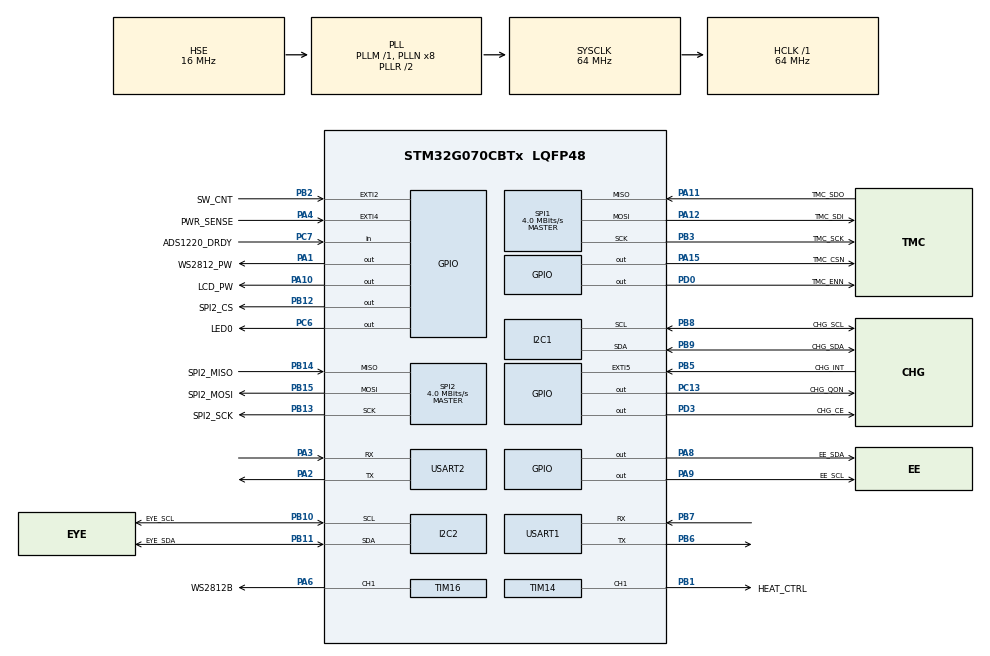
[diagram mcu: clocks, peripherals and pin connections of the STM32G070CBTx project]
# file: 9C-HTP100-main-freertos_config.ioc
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Dma.I2C1_RX.0.Direction=DMA_PERIPH_TO_MEMORY
Dma.I2C1_RX.0.EventEnable=DISABLE
Dma.I2C1_RX.0.Instance=DMA1_Channel1
Dma.I2C1_RX.0.MemDataAlignment=DMA_MDATAALIGN_BYTE
Dma.I2C1_RX.0.MemInc=DMA_MINC_ENABLE
Dma.I2C1_RX.0.Mode=DMA_NORMAL
Dma.I2C1_RX.0.PeriphDataAlignment=DMA_PDATAALIGN_BYTE
Dma.I2C1_RX.0.PeriphInc=DMA_PINC_DISABLE
Dma.I2C1_RX.0.Polarity=HAL_DMAMUX_REQ_GEN_RISING
Dma.I2C1_RX.0.Priority=DMA_PRIORITY_LOW
Dma.I2C1_RX.0.RequestNumber=1
Dma.I2C1_RX.0.SignalID=NONE
Dma.I2C1_RX.0.SyncEnable=DISABLE
Dma.I2C1_RX.0.SyncPolarity=HAL_DMAMUX_SYNC_NO_EVENT
Dma.I2C1_RX.0.SyncRequestNumber=1
Dma.I2C1_RX.0.SyncSignalID=NONE
Dma.I2C1_TX.1.Direction=DMA_MEMORY_TO_PERIPH
Dma.I2C1_TX.1.EventEnable=DISABLE
Dma.I2C1_TX.1.Instance=DMA1_Channel2
Dma.I2C1_TX.1.MemDataAlignment=DMA_MDATAALIGN_BYTE
Dma.I2C1_TX.1.MemInc=DMA_MINC_ENABLE
Dma.I2C1_TX.1.Mode=DMA_NORMAL
Dma.I2C1_TX.1.PeriphDataAlignment=DMA_PDATAALIGN_BYTE
Dma.I2C1_TX.1.PeriphInc=DMA_PINC_DISABLE
Dma.I2C1_TX.1.Polarity=HAL_DMAMUX_REQ_GEN_RISING
Dma.I2C1_TX.1.Priority=DMA_PRIORITY_LOW
Dma.I2C1_TX.1.RequestNumber=1
Dma.I2C1_TX.1.SignalID=NONE
Dma.I2C1_TX.1.SyncEnable=DISABLE
Dma.I2C1_TX.1.SyncPolarity=HAL_DMAMUX_SYNC_NO_EVENT
Dma.I2C1_TX.1.SyncRequestNumber=1
Dma.I2C1_TX.1.SyncSignalID=NONE
Dma.I2C2_RX.2.Direction=DMA_PERIPH_TO_MEMORY
Dma.I2C2_RX.2.EventEnable=DISABLE
Dma.I2C2_RX.2.Instance=DMA1_Channel3
Dma.I2C2_RX.2.MemDataAlignment=DMA_MDATAALIGN_BYTE
Dma.I2C2_RX.2.MemInc=DMA_MINC_ENABLE
Dma.I2C2_RX.2.Mode=DMA_NORMAL
Dma.I2C2_RX.2.PeriphDataAlignment=DMA_PDATAALIGN_BYTE
Dma.I2C2_RX.2.PeriphInc=DMA_PINC_DISABLE
Dma.I2C2_RX.2.Polarity=HAL_DMAMUX_REQ_GEN_RISING
Dma.I2C2_RX.2.Priority=DMA_PRIORITY_LOW
Dma.I2C2_RX.2.RequestNumber=1
Dma.I2C2_RX.2.SignalID=NONE
Dma.I2C2_RX.2.SyncEnable=DISABLE
Dma.I2C2_RX.2.SyncPolarity=HAL_DMAMUX_SYNC_NO_EVENT
Dma.I2C2_RX.2.SyncRequestNumber=1
Dma.I2C2_RX.2.SyncSignalID=NONE
Dma.I2C2_TX.3.Direction=DMA_MEMORY_TO_PERIPH
Dma.I2C2_TX.3.EventEnable=DISABLE
Dma.I2C2_TX.3.Instance=DMA1_Channel4
Dma.I2C2_TX.3.MemDataAlignment=DMA_MDATAALIGN_BYTE
Dma.I2C2_TX.3.MemInc=DMA_MINC_ENABLE
Dma.I2C2_TX.3.Mode=DMA_NORMAL
Dma.I2C2_TX.3.PeriphDataAlignment=DMA_PDATAALIGN_BYTE
Dma.I2C2_TX.3.PeriphInc=DMA_PINC_DISABLE
Dma.I2C2_TX.3.Polarity=HAL_DMAMUX_REQ_GEN_RISING
Dma.I2C2_TX.3.Priority=DMA_PRIORITY_LOW
Dma.I2C2_TX.3.RequestNumber=1
Dma.I2C2_TX.3.SignalID=NONE
Dma.I2C2_TX.3.SyncEnable=DISABLE
Dma.I2C2_TX.3.SyncPolarity=HAL_DMAMUX_SYNC_NO_EVENT
Dma.I2C2_TX.3.SyncRequestNumber=1
Dma.I2C2_TX.3.SyncSignalID=NONE
Dma.Request0=I2C1_RX
Dma.Request1=I2C1_TX
Dma.Request2=I2C2_RX
Dma.Request3=I2C2_TX
Dma.Request4=TIM16_CH1
Dma.Request5=USART2_RX
Dma.TIM16_CH1.4.Direction=DMA_MEMORY_TO_PERIPH
Dma.TIM16_CH1.4.EventEnable=DISABLE
Dma.TIM16_CH1.4.Instance=DMA1_Channel7
Dma.TIM16_CH1.4.MemDataAlignment=DMA_MDATAALIGN_HALFWORD
Dma.TIM16_CH1.4.MemInc=DMA_MINC_ENABLE
Dma.TIM16_CH1.4.Mode=DMA_CIRCULAR
Dma.TIM16_CH1.4.PeriphDataAlignment=DMA_PDATAALIGN_HALFWORD
Dma.TIM16_CH1.4.PeriphInc=DMA_PINC_DISABLE
Dma.TIM16_CH1.4.Polarity=HAL_DMAMUX_REQ_GEN_RISING
Dma.TIM16_CH1.4.Priority=DMA_PRIORITY_LOW
Dma.TIM16_CH1.4.RequestNumber=1
Dma.TIM16_CH1.4.SignalID=NONE
Dma.TIM16_CH1.4.SyncEnable=DISABLE
Dma.TIM16_CH1.4.SyncPolarity=HAL_DMAMUX_SYNC_NO_EVENT
Dma.TIM16_CH1.4.SyncRequestNumber=1
Dma.TIM16_CH1.4.SyncSignalID=NONE
Dma.USART2_RX.5.Direction=DMA_PERIPH_TO_MEMORY
Dma.USART2_RX.5.EventEnable=DISABLE
Dma.USART2_RX.5.Instance=DMA1_Channel5
Dma.USART2_RX.5.MemDataAlignment=DMA_MDATAALIGN_BYTE
Dma.USART2_RX.5.MemInc=DMA_MINC_ENABLE
Dma.USART2_RX.5.Mode=DMA_NORMAL
Dma.USART2_RX.5.PeriphDataAlignment=DMA_PDATAALIGN_BYTE
Dma.USART2_RX.5.PeriphInc=DMA_PINC_DISABLE
Dma.USART2_RX.5.Polarity=HAL_DMAMUX_REQ_GEN_RISING
Dma.USART2_RX.5.Priority=DMA_PRIORITY_VERY_HIGH
Dma.USART2_RX.5.RequestNumber=1
Dma.USART2_RX.5.SignalID=NONE
Dma.USART2_RX.5.SyncEnable=DISABLE
Dma.USART2_RX.5.SyncPolarity=HAL_DMAMUX_SYNC_NO_EVENT
Dma.USART2_RX.5.SyncRequestNumber=1
Dma.USART2_RX.5.SyncSignalID=NONE
FREERTOS.BinarySemaphores01=BUTTON_SEMAPHORE,Dynamic,NULL
FREERTOS.Events01=HEAT_ON,Dynamic,NULL;PRESS_ON,Dynamic,NULL
FREERTOS.Queues01=UART_DMA_IDLE_RECEPT_QUEUE,3,uart_data *,0,Dynamic,NULL,NULL;HEAT_DATA,5,PID_TypeDef,0,Dynamic,NULL,NULL;PRESS_DATA,5,PID_TypeDef,0,Dynamic,NULL,NULL;Temperature,5,float,0,Dynamic,NULL,NULL;Pressure,5,float,0,Dynamic,NULL,NULL;Battery_DATA,5,float,0,Dynamic,NULL,NULL;prepare_data,10,prepare_data,0,Dynamic,NULL,NULL
FREERTOS.Tasks01=UART_RECEPT,41,256,UART_RECEPT_Task,Default,NULL,Dynamic,NULL,NULL;Heat,41,256,Heat_Task,Default,NULL,Dynamic,NULL,NULL;Press,40,256,Press_Task,Default,NULL,Dynamic,NULL,NULL;Button_State,41,256,Button_State_Task,Default,NULL,Dynamic,NULL,NULL;APP,40,256,APP_task,Default,NULL,Dynamic,NULL,NULL;Uart_send,24,256,Uart_send_task,Default,NULL,Dynamic,NULL,NULL;AD24C01,24,128,AD24C01_WR,Default,NULL,Dynamic,NULL,NULL
FREERTOS.Timers01=ws2812_white_delay,ws2812_white_delay_callback,osTimerOnce,Default,NULL,Dynamic,NULL;ws2812_yellow_delay,ws2812_yellow_callback,osTimerOnce,Default,NULL,Dynamic,NULL;breath_delay,breath_delay_Callback,osTimerOnce,Default,NULL,Dynamic,NULL;motor_grab3s,motor_grab3s_Callback,osTimerOnce,Default,NULL,Dynamic,NULL;motor_back_1s,motor_back_1sCallback,osTimerOnce,Default,NULL,Dynamic,NULL;buttton,buttton_Callback,osTimerPeriodic,Default,NULL,Dynamic,NULL;tempareture_pid,tempareture_pid_timer,osTimerPeriodic,Default,NULL,Dynamic,NULL
FREERTOS.configENABLE_FPU=1
FREERTOS.configGENERATE_RUN_TIME_STATS=1
FREERTOS.configMAX_CO_ROUTINE_PRIORITIES=20
FREERTOS.configMINIMAL_STACK_SIZE=64
FREERTOS.configRECORD_STACK_HIGH_ADDRESS=1
FREERTOS.configTIMER_TASK_PRIORITY=55
FREERTOS.configTOTAL_HEAP_SIZE=11000
FREERTOS.configUSE_CO_ROUTINES=1
FREERTOS.configUSE_OS2_THREAD_ENUMERATE=1
FREERTOS.configUSE_STATS_FORMATTING_FUNCTIONS=1
FREERTOS.configUSE_TRACE_FACILITY=1
I2C1.CustomTiming=Disabled
I2C1.Timing=0x10707DBC
I2C2.Timing=0x10707DBC
Mcu.Family=STM32G0
Mcu.Name=STM32G070CBTx
Mcu.Package=LQFP48
NVIC.DMA1_Ch4_7_DMAMUX1_OVR_IRQn=true\:3\:0\:true\:false\:true\:true\:false\:true\:true
NVIC.DMA1_Channel1_IRQn=true\:3\:0\:true\:false\:true\:true\:false\:true\:true
NVIC.DMA1_Channel2_3_IRQn=true\:3\:0\:true\:false\:true\:true\:false\:true\:true
NVIC.EXTI2_3_IRQn=true\:3\:0\:false\:false\:true\:true\:true\:true\:true
NVIC.EXTI4_15_IRQn=true\:2\:0\:true\:false\:true\:false\:true\:true\:true
NVIC.I2C1_IRQn=true\:3\:0\:false\:false\:true\:true\:true\:true\:true
NVIC.I2C2_IRQn=true\:3\:0\:false\:false\:true\:true\:true\:true\:true
NVIC.SPI1_IRQn=true\:0\:0\:true\:false\:true\:false\:true\:true\:true
NVIC.SPI2_IRQn=true\:3\:0\:false\:false\:true\:true\:true\:true\:true
NVIC.TIM14_IRQn=true\:3\:0\:false\:false\:true\:true\:true\:true\:true
NVIC.TIM16_IRQn=true\:3\:0\:false\:false\:true\:true\:true\:true\:true
NVIC.TIM17_IRQn=true\:3\:0\:false\:false\:true\:true\:true\:true\:true
NVIC.TIM6_IRQn=true\:3\:0\:true\:false\:true\:false\:true\:true\:true
NVIC.TIM7_IRQn=true\:3\:0\:false\:false\:true\:true\:true\:true\:true
NVIC.TimeBase=TIM6_IRQn
NVIC.TimeBaseIP=TIM6
NVIC.USART2_IRQn=true\:3\:0\:false\:false\:true\:true\:true\:true\:true
PA1.GPIO_Label=WS2812_PW
PA1.GPIO_ModeDefaultOutputPP=GPIO_MODE_OUTPUT_PP
PA1.GPIO_PuPd=GPIO_PULLDOWN
PA1.GPIO_Speed=GPIO_SPEED_FREQ_LOW
PA1.PinState=GPIO_PIN_SET
PA1.Signal=GPIO_Output
PA10.GPIO_FMPA10=__NULL
PA10.GPIO_Label=LCD_PW
PA10.GPIO_ModeDefaultOutputPP=GPIO_MODE_OUTPUT_OD
PA10.GPIO_PuPd=GPIO_NOPULL
PA10.PinState=GPIO_PIN_RESET
PA10.Signal=GPIO_Output
PA11\ [PA9].GPIO_Label=TMC_SDO
PA11\ [PA9].Mode=Full_Duplex_Master
PA11\ [PA9].Signal=SPI1_MISO
PA12\ [PA10].GPIO_Label=TMC_SDI
PA12\ [PA10].Mode=Full_Duplex_Master
PA12\ [PA10].Signal=SPI1_MOSI
PA13.Mode=Serial_Wire
PA13.Signal=SYS_SWDIO
PA14-BOOT0.Mode=Serial_Wire
PA14-BOOT0.Signal=SYS_SWCLK
PA15.GPIO_Label=TMC_CSN
PA15.PinState=GPIO_PIN_SET
PA15.Signal=GPIO_Output
PA2.GPIO_PuPd=GPIO_NOPULL
PA2.Mode=Asynchronous
PA2.Signal=USART2_TX
PA3.GPIO_PuPd=GPIO_PULLUP
PA3.Mode=Asynchronous
PA3.Signal=USART2_RX
PA4.GPIO_Label=PWR_SENSE
PA4.GPIO_ModeDefaultEXTI=GPIO_MODE_IT_RISING
PA4.GPIO_PuPd=GPIO_PULLDOWN
PA4.Signal=GPXTI4
PA6.GPIO_Label=WS2812B
PA6.GPIO_Speed=GPIO_SPEED_FREQ_VERY_HIGH
PA6.Signal=S_TIM16_CH1
PA8.GPIO_Label=EE_SDA
PA8.GPIO_ModeDefaultOutputPP=GPIO_MODE_OUTPUT_OD
PA8.GPIO_PuPd=GPIO_NOPULL
PA8.GPIO_Speed=GPIO_SPEED_FREQ_VERY_HIGH
PA8.Signal=GPIO_Output
PA9.GPIO_FMPA9=SYSCFG_FASTMODEPLUS_PA9
PA9.GPIO_Label=EE_SCL
PA9.GPIO_ModeDefaultOutputPP=GPIO_MODE_OUTPUT_OD
PA9.GPIO_PuPd=GPIO_NOPULL
PA9.GPIO_Speed=GPIO_SPEED_FREQ_VERY_HIGH
PA9.Signal=GPIO_Output
PB1.GPIO_Label=HEAT_CTRL
PB1.Signal=S_TIM14_CH1
PB10.GPIO_Label=EYE_SCL
PB10.Mode=I2C
PB10.Signal=I2C2_SCL
PB11.GPIO_Label=EYE_SDA
PB11.Mode=I2C
PB11.Signal=I2C2_SDA
PB12.GPIO_Label=SPI2_CS
PB12.GPIO_PuPd=GPIO_PULLUP
PB12.PinState=GPIO_PIN_SET
PB12.Signal=GPIO_Output
PB13.GPIO_Label=SPI2_SCK
PB13.Mode=Full_Duplex_Master
PB13.Signal=SPI2_SCK
PB14.GPIO_Label=SPI2_MISO
PB14.Mode=Full_Duplex_Master
PB14.Signal=SPI2_MISO
PB15.GPIO_Label=SPI2_MOSI
PB15.Mode=Full_Duplex_Master
PB15.Signal=SPI2_MOSI
PB2.GPIO_Label=SW_CNT
PB2.GPIO_ModeDefaultEXTI=GPIO_MODE_IT_FALLING
PB2.Signal=GPXTI2
PB3.GPIO_Label=TMC_SCK
PB3.Mode=Full_Duplex_Master
PB3.Signal=SPI1_SCK
PB5.GPIO_Label=CHG_INT
PB5.Signal=GPXTI5
PB6.Mode=Asynchronous
PB6.Signal=USART1_TX
PB7.Mode=Asynchronous
PB7.Signal=USART1_RX
PB8.GPIO_Label=CHG_SCL
PB8.Mode=I2C
PB8.Signal=I2C1_SCL
PB9.GPIO_Label=CHG_SDA
PB9.Mode=I2C
PB9.Signal=I2C1_SDA
PC13.GPIO_Label=CHG_QON
PC13.Signal=GPIO_Output
PC14-OSC32_IN\ (PC14).Mode=LSE-External-Oscillator
PC14-OSC32_IN\ (PC14).Signal=RCC_OSC32_IN
PC15-OSC32_OUT\ (PC15).Mode=LSE-External-Oscillator
PC15-OSC32_OUT\ (PC15).Signal=RCC_OSC32_OUT
PC6.GPIO_Label=LED0
PC6.PinState=GPIO_PIN_SET
PC6.Signal=GPIO_Output
PC7.GPIO_Label=ADS1220_DRDY
PC7.Signal=GPIO_Input
PD0.GPIO_Label=TMC_ENN
PD0.PinState=GPIO_PIN_SET
PD0.Signal=GPIO_Output
PD3.GPIO_Label=CHG_CE
PD3.GPIO_PuPd=GPIO_NOPULL
PD3.PinState=GPIO_PIN_SET
PD3.Signal=GPIO_Output
PF0-OSC_IN\ (PF0).Mode=HSE-External-Oscillator
PF0-OSC_IN\ (PF0).Signal=RCC_OSC_IN
PF1-OSC_OUT\ (PF1).Mode=HSE-External-Oscillator
PF1-OSC_OUT\ (PF1).Signal=RCC_OSC_OUT
ProjectManager.HeapSize=0x200
ProjectManager.StackSize=0x400
ProjectManager.TargetToolchain=CMake
RCC.ADCFreq_Value=64000000
RCC.AHBFreq_Value=64000000
RCC.CortexFreq_Value=64000000
RCC.EXTERNAL_CLOCK_VALUE=48000
RCC.HCLKFreq_Value=64000000
RCC.HSE_VALUE=16000000
RCC.HSI_VALUE=16000000
RCC.PLLP=RCC_PLLP_DIV4
RCC.PLLSourceVirtual=RCC_PLLSOURCE_HSE
RCC.SYSCLKFreq_VALUE=64000000
RCC.SYSCLKSource=RCC_SYSCLKSOURCE_PLLCLK
RCC.VCOOutputFreq_Value=128000000
SH.S_TIM14_CH1.0=TIM14_CH1,PWM Generation1 CH1
SH.S_TIM16_CH1.0=TIM16_CH1,PWM Generation1 CH1
SPI1.BaudRatePrescaler=SPI_BAUDRATEPRESCALER_16
SPI1.CLKPhase=SPI_PHASE_2EDGE
SPI1.CLKPolarity=SPI_POLARITY_HIGH
SPI1.CalculateBaudRate=4.0 MBits/s
SPI1.DataSize=SPI_DATASIZE_8BIT
SPI1.Direction=SPI_DIRECTION_2LINES
SPI1.Mode=SPI_MODE_MASTER
SPI1.VirtualType=VM_MASTER
SPI2.BaudRatePrescaler=SPI_BAUDRATEPRESCALER_16
SPI2.CLKPhase=SPI_PHASE_2EDGE
SPI2.CalculateBaudRate=4.0 MBits/s
SPI2.DataSize=SPI_DATASIZE_8BIT
SPI2.Direction=SPI_DIRECTION_2LINES
SPI2.Mode=SPI_MODE_MASTER
SPI2.VirtualType=VM_MASTER
TIM14.Channel=TIM_CHANNEL_1
TIM14.Period=255
TIM14.Prescaler=63
TIM16.AutoReloadPreload=TIM_AUTORELOAD_PRELOAD_DISABLE
TIM16.Channel=TIM_CHANNEL_1
TIM16.Period=80
TIM16.Prescaler=0
TIM17.Period=999
TIM17.Prescaler=63
TIM7.Prescaler=63
USART1.VirtualMode-Asynchronous=VM_ASYNC
USART2.VirtualMode-Asynchronous=VM_ASYNC
VP_FREERTOS_VS_CMSIS_V2.Mode=CMSIS_V2
VP_SYS_VS_DBSignals.Mode=DisableDeadBatterySignals
VP_SYS_VS_tim6.Mode=TIM6
VP_TIM14_VS_ClockSourceINT.Mode=Enable_Timer
VP_TIM16_VS_ClockSourceINT.Mode=Enable_Timer
VP_TIM17_VS_ClockSourceINT.Mode=Enable_Timer
VP_TIM7_VS_ClockSourceINT.Mode=Enable_Timer
board=custom

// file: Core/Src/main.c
/* USER CODE BEGIN Header */
/**
  ******************************************************************************
  * @file           : main.c
  * @brief          : Main program body
  ******************************************************************************
  * @attention
  *
  * Copyright (c) 2024 STMicroelectronics.
  * All rights reserved.
  *
  * This software is licensed under terms that can be found in the LICENSE file
  * in the root directory of this software component.
  * If no LICENSE file comes with this software, it is provided AS-IS.
  *
  ******************************************************************************
  */
/* USER CODE END Header */
#include "main.h"
#include "cmsis_os.h"
#include "dma.h"
#include "i2c.h"
#include "spi.h"
#include "tim.h"
#include "usart.h"
#include "gpio.h"

/* USER CODE BEGIN Includes */
#include "interface_uart.h"

/* USER CODE END Includes */

void SystemClock_Config(void);
void MX_FREERTOS_Init(void);

int main(void)
{

  /* MCU Configuration--------------------------------------------------------*/

  /* Reset of all peripherals, Initializes the Flash interface and the Systick. */
  HAL_Init();

  /* Configure the system clock */
  SystemClock_Config();

  /* Initialize all configured peripherals */
  MX_GPIO_Init();
  MX_DMA_Init();
  MX_I2C1_Init();
  MX_I2C2_Init();
  MX_SPI1_Init();
  MX_TIM14_Init();
  MX_TIM16_Init();
  MX_TIM17_Init();
  MX_SPI2_Init();
  MX_USART2_UART_Init();
  MX_TIM7_Init();
  MX_USART1_UART_Init();

  /* Init scheduler */
  osKernelInitialize();  /* Call init function for freertos objects (in cmsis_os2.c) */
  MX_FREERTOS_Init();

  /* Start scheduler */
  osKernelStart();

  /* We should never get here as control is now taken by the scheduler */

  /* Infinite loop */
  while (1)
  {

  }
}

void SystemClock_Config(void)
{
  RCC_OscInitTypeDef RCC_OscInitStruct = {0};
  RCC_ClkInitTypeDef RCC_ClkInitStruct = {0};

  /** Configure the main internal regulator output voltage
  */
  HAL_PWREx_ControlVoltageScaling(PWR_REGULATOR_VOLTAGE_SCALE1);

  /** Initializes the RCC Oscillators according to the specified parameters
  * in the RCC_OscInitTypeDef structure.
  */
  RCC_OscInitStruct.OscillatorType = RCC_OSCILLATORTYPE_HSE;
  RCC_OscInitStruct.HSEState = RCC_HSE_ON;
  RCC_OscInitStruct.PLL.PLLState = RCC_PLL_ON;
  RCC_OscInitStruct.PLL.PLLSource = RCC_PLLSOURCE_HSE;
  RCC_OscInitStruct.PLL.PLLM = RCC_PLLM_DIV1;
  RCC_OscInitStruct.PLL.PLLN = 8;
  RCC_OscInitStruct.PLL.PLLP = RCC_PLLP_DIV4;
  RCC_OscInitStruct.PLL.PLLR = RCC_PLLR_DIV2;
  if (HAL_RCC_OscConfig(&RCC_OscInitStruct) != HAL_OK)
  {
    Error_Handler();
  }

  /** Initializes the CPU, AHB and APB buses clocks
  */
  RCC_ClkInitStruct.ClockType = RCC_CLOCKTYPE_HCLK|RCC_CLOCKTYPE_SYSCLK
                              |RCC_CLOCKTYPE_PCLK1;
  RCC_ClkInitStruct.SYSCLKSource = RCC_SYSCLKSOURCE_PLLCLK;
  RCC_ClkInitStruct.AHBCLKDivider = RCC_SYSCLK_DIV1;
  RCC_ClkInitStruct.APB1CLKDivider = RCC_HCLK_DIV1;

  if (HAL_RCC_ClockConfig(&RCC_ClkInitStruct, FLASH_LATENCY_2) != HAL_OK)
  {
    Error_Handler();
  }

  /** Enables the Clock Security System
  */
  HAL_RCC_EnableCSS();
}

/* USER CODE BEGIN 4 */
volatile uint8_t flag_5ms = 0;  // 5ms ��־λ
volatile uint8_t flag_10ms = 0; // 10ms ��־λ
volatile uint16_t counter_ms = 0; // ���������
/* USER CODE END 4 */

void HAL_TIM_PeriodElapsedCallback(TIM_HandleTypeDef *htim)
{
  if (htim->Instance == TIM6)
  {
    HAL_IncTick();
  }
  /* USER CODE BEGIN Callback 1 */
if (htim == &htim17) {
        counter_ms++; // �������������

        // ÿ 5ms ����һ�α�־λ
        if (counter_ms % 6 == 0) {
            flag_5ms = 1;

        }
        // ÿ 10ms ����һ�α�־λ
        if (counter_ms % 10 == 0) {
            flag_10ms = 1;

        }

        // // ��ֹ������������� 1s ����㣩
        // if (counter_ms >= 1000) {
        //     counter_ms = 0;
        // }
    }

  /* USER CODE END Callback 1 */
}

void Error_Handler(void)
{
  /* USER CODE BEGIN Error_Handler_Debug */
  /* User can add his own implementation to report the HAL error return state */
    LOGE("[System] Event\n");
  __disable_irq();

    while (1)
  {
  }
  /* USER CODE END Error_Handler_Debug */
}

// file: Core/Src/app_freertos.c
/* USER CODE BEGIN Header */
/* USER CODE END Header */

#include "FreeRTOS.h"
#include "task.h"
#include "main.h"
#include "cmsis_os.h"

/* USER CODE BEGIN Includes */
#include "UserApp.h"
/* USER CODE END Includes */

/* Definitions for freertos_main */
osThreadId_t freertos_mainHandle;
const osThreadAttr_t freertos_main_attributes = {
  .name = "freertos_main",
  .priority = (osPriority_t) osPriorityHigh,
  .stack_size = 1024 * 2
};

void freertos_main_Task(void *argument);

void MX_FREERTOS_Init(void); /* (MISRA C 2004 rule 8.1) */

/* Hook prototypes */
void configureTimerForRunTimeStats(void);
unsigned long getRunTimeCounterValue(void);

void MX_FREERTOS_Init(void) {

  /* Create the thread(s) */
  /* creation of freertos_main */
  freertos_mainHandle = osThreadNew(freertos_main_Task, NULL, &freertos_main_attributes);

}

void freertos_main_Task(void *argument)
{
  /* USER CODE BEGIN freertos_main_Task */
    //osDelay(1000);
    Main();
    vTaskDelete(freertos_mainHandle);
  /* USER CODE END freertos_main_Task */
}
